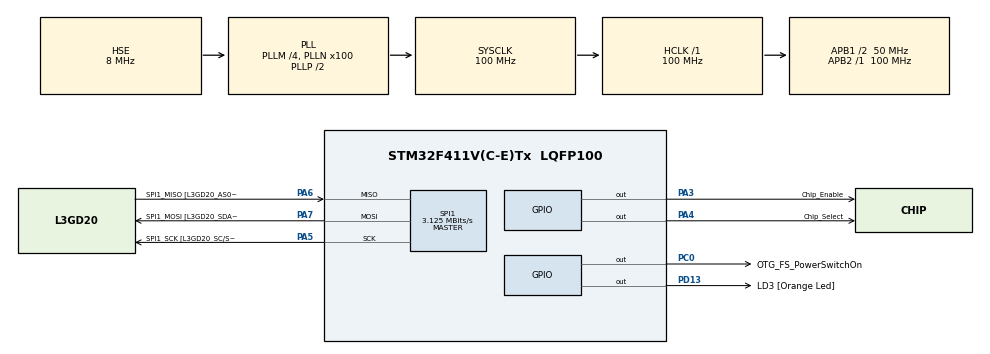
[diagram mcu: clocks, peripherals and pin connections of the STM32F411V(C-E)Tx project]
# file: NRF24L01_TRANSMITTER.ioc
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Mcu.Family=STM32F4
Mcu.Name=STM32F411V(C-E)Tx
Mcu.Package=LQFP100
NVIC.PriorityGroup=NVIC_PRIORITYGROUP_0
PA13.GPIO_Label=SWDIO
PA13.Mode=Serial_Wire
PA13.Signal=SYS_JTMS-SWDIO
PA14.GPIO_Label=SWCLK
PA14.Mode=Serial_Wire
PA14.Signal=SYS_JTCK-SWCLK
PA3.GPIO_Label=Chip_Enable
PA3.GPIO_PuPd=GPIO_PULLDOWN
PA3.GPIO_Speed=GPIO_SPEED_FREQ_MEDIUM
PA3.Signal=GPIO_Output
PA4.GPIO_Label=Chip_Select
PA4.GPIO_PuPd=GPIO_PULLUP
PA4.GPIO_Speed=GPIO_SPEED_FREQ_HIGH
PA4.PinState=GPIO_PIN_SET
PA4.Signal=GPIO_Output
PA5.GPIO_Label=SPI1_SCK [L3GD20_SC/SPC]
PA5.Mode=Full_Duplex_Master
PA5.Signal=SPI1_SCK
PA6.GPIO_Label=SPI1_MISO [L3GD20_AS0/SDO]
PA6.Mode=Full_Duplex_Master
PA6.Signal=SPI1_MISO
PA7.GPIO_Label=SPI1_MOSI [L3GD20_SDA/SDI/SDO]
PA7.Mode=Full_Duplex_Master
PA7.Signal=SPI1_MOSI
PB3.Signal=SYS_JTDO-SWO
PC0.GPIO_Label=OTG_FS_PowerSwitchOn
PC0.PinState=GPIO_PIN_SET
PC0.Signal=GPIO_Output
PD13.GPIO_Label=LD3 [Orange Led]
PD13.GPIO_PuPd=GPIO_NOPULL
PD13.GPIO_Speed=GPIO_SPEED_FREQ_LOW
PD13.Signal=GPIO_Output
PH0\ -\ OSC_IN.Mode=HSE-External-Oscillator
PH0\ -\ OSC_IN.Signal=RCC_OSC_IN
PH1\ -\ OSC_OUT.Mode=HSE-External-Oscillator
PH1\ -\ OSC_OUT.Signal=RCC_OSC_OUT
ProjectManager.HeapSize=0x200
ProjectManager.StackSize=0x400
ProjectManager.TargetToolchain=STM32CubeIDE
RCC.48MHZClocksFreq_Value=25000000
RCC.AHBFreq_Value=100000000
RCC.APB1CLKDivider=RCC_HCLK_DIV2
RCC.APB1Freq_Value=50000000
RCC.APB1TimFreq_Value=100000000
RCC.APB2Freq_Value=100000000
RCC.APB2TimFreq_Value=100000000
RCC.CortexFreq_Value=100000000
RCC.HCLKFreq_Value=100000000
RCC.HSE_VALUE=8000000
RCC.HSI_VALUE=16000000
RCC.PLLI2SM=5
RCC.PLLI2SN=200
RCC.PLLM=4
RCC.PLLN=100
RCC.PLLQ=8
RCC.PLLSourceVirtual=RCC_PLLSOURCE_HSE
RCC.SYSCLKFreq_VALUE=100000000
RCC.SYSCLKSource=RCC_SYSCLKSOURCE_PLLCLK
RCC.VCOOutputFreq_Value=200000000
SPI1.BaudRatePrescaler=SPI_BAUDRATEPRESCALER_32
SPI1.CalculateBaudRate=3.125 MBits/s
SPI1.Direction=SPI_DIRECTION_2LINES
SPI1.Mode=SPI_MODE_MASTER
SPI1.VirtualType=VM_MASTER
board=STM32F411E-DISCO

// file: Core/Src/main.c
/* USER CODE BEGIN Header */
/**
  ******************************************************************************
  * @file           : main.c
  * @brief          : Main program body
  ******************************************************************************
  * @attention
  *
  * Copyright (c) 2024 STMicroelectronics.
  * All rights reserved.
  *
  * This software is licensed under terms that can be found in the LICENSE file
  * in the root directory of this software component.
  * If no LICENSE file comes with this software, it is provided AS-IS.
  *
  ******************************************************************************
  */
/* USER CODE END Header */
#include "main.h"

/* USER CODE BEGIN Includes */
#include "NRF24L01.h"
#include "string.h"
#include "stdio.h"
/* USER CODE END Includes */

SPI_HandleTypeDef hspi1;

void SystemClock_Config(void);
static void MX_GPIO_Init(void);
static void MX_SPI1_Init(void);

/* USER CODE BEGIN 0 */
//uint8_t data[50];
uint8_t TxAddress[] = {0xAA, 0xBB, 0xCC, 0xDD, 0x11};  // 5-byte address for Pipe 1
uint8_t TxData[] = "Hello World\n";  // Transmitted data

/* USER CODE END 0 */

int main(void)
{

  /* MCU Configuration--------------------------------------------------------*/

  /* Reset of all peripherals, Initializes the Flash interface and the Systick. */
  HAL_Init();

  /* Configure the system clock */
  SystemClock_Config();

  /* Initialize all configured peripherals */
  MX_GPIO_Init();
  MX_SPI1_Init();
  /* USER CODE BEGIN 2 */
  NRF24_Init();

 // NRF24_RxMode(RxAddress, 10);

 NRF24_TxMode(TxAddress, 10);
  /* USER CODE END 2 */

  /* Infinite loop */
  while (1)
  {

    /* USER CODE BEGIN 3 */
	  if (NRF24_Transmit(TxData) == 1)
	   	  {
	   		  HAL_GPIO_TogglePin(GPIOD, GPIO_PIN_13);
	   	  }

	   	  HAL_Delay(1000);

  }
  /* USER CODE END 3 */
}

void SystemClock_Config(void)
{
  RCC_OscInitTypeDef RCC_OscInitStruct = {0};
  RCC_ClkInitTypeDef RCC_ClkInitStruct = {0};

  /** Configure the main internal regulator output voltage
  */
  __HAL_RCC_PWR_CLK_ENABLE();
  __HAL_PWR_VOLTAGESCALING_CONFIG(PWR_REGULATOR_VOLTAGE_SCALE1);

  /** Initializes the RCC Oscillators according to the specified parameters
  * in the RCC_OscInitTypeDef structure.
  */
  RCC_OscInitStruct.OscillatorType = RCC_OSCILLATORTYPE_HSE;
  RCC_OscInitStruct.HSEState = RCC_HSE_ON;
  RCC_OscInitStruct.PLL.PLLState = RCC_PLL_ON;
  RCC_OscInitStruct.PLL.PLLSource = RCC_PLLSOURCE_HSE;
  RCC_OscInitStruct.PLL.PLLM = 4;
  RCC_OscInitStruct.PLL.PLLN = 100;
  RCC_OscInitStruct.PLL.PLLP = RCC_PLLP_DIV2;
  RCC_OscInitStruct.PLL.PLLQ = 8;
  if (HAL_RCC_OscConfig(&RCC_OscInitStruct) != HAL_OK)
  {
    Error_Handler();
  }

  /** Initializes the CPU, AHB and APB buses clocks
  */
  RCC_ClkInitStruct.ClockType = RCC_CLOCKTYPE_HCLK|RCC_CLOCKTYPE_SYSCLK
                              |RCC_CLOCKTYPE_PCLK1|RCC_CLOCKTYPE_PCLK2;
  RCC_ClkInitStruct.SYSCLKSource = RCC_SYSCLKSOURCE_PLLCLK;
  RCC_ClkInitStruct.AHBCLKDivider = RCC_SYSCLK_DIV1;
  RCC_ClkInitStruct.APB1CLKDivider = RCC_HCLK_DIV2;
  RCC_ClkInitStruct.APB2CLKDivider = RCC_HCLK_DIV1;

  if (HAL_RCC_ClockConfig(&RCC_ClkInitStruct, FLASH_LATENCY_3) != HAL_OK)
  {
    Error_Handler();
  }
}

static void MX_SPI1_Init(void)
{

  /* SPI1 parameter configuration*/
  hspi1.Instance = SPI1;
  hspi1.Init.Mode = SPI_MODE_MASTER;
  hspi1.Init.Direction = SPI_DIRECTION_2LINES;
  hspi1.Init.DataSize = SPI_DATASIZE_8BIT;
  hspi1.Init.CLKPolarity = SPI_POLARITY_LOW;
  hspi1.Init.CLKPhase = SPI_PHASE_1EDGE;
  hspi1.Init.NSS = SPI_NSS_SOFT;
  hspi1.Init.BaudRatePrescaler = SPI_BAUDRATEPRESCALER_32;
  hspi1.Init.FirstBit = SPI_FIRSTBIT_MSB;
  hspi1.Init.TIMode = SPI_TIMODE_DISABLE;
  hspi1.Init.CRCCalculation = SPI_CRCCALCULATION_DISABLE;
  hspi1.Init.CRCPolynomial = 10;
  if (HAL_SPI_Init(&hspi1) != HAL_OK)
  {
    Error_Handler();
  }

}

static void MX_GPIO_Init(void)
{
  GPIO_InitTypeDef GPIO_InitStruct = {0};

  /* GPIO Ports Clock Enable */
  __HAL_RCC_GPIOH_CLK_ENABLE();
  __HAL_RCC_GPIOC_CLK_ENABLE();
  __HAL_RCC_GPIOA_CLK_ENABLE();
  __HAL_RCC_GPIOD_CLK_ENABLE();
  __HAL_RCC_GPIOB_CLK_ENABLE();

  /*Configure GPIO pin Output Level */
  HAL_GPIO_WritePin(OTG_FS_PowerSwitchOn_GPIO_Port, OTG_FS_PowerSwitchOn_Pin, GPIO_PIN_SET);

  /*Configure GPIO pin Output Level */
  HAL_GPIO_WritePin(Chip_Enable_GPIO_Port, Chip_Enable_Pin, GPIO_PIN_RESET);

  /*Configure GPIO pin Output Level */
  HAL_GPIO_WritePin(Chip_Select_GPIO_Port, Chip_Select_Pin, GPIO_PIN_SET);

  /*Configure GPIO pin Output Level */
  HAL_GPIO_WritePin(LD3_GPIO_Port, LD3_Pin, GPIO_PIN_RESET);

  /*Configure GPIO pin : OTG_FS_PowerSwitchOn_Pin */
  GPIO_InitStruct.Pin = OTG_FS_PowerSwitchOn_Pin;
  GPIO_InitStruct.Mode = GPIO_MODE_OUTPUT_PP;
  GPIO_InitStruct.Pull = GPIO_NOPULL;
  GPIO_InitStruct.Speed = GPIO_SPEED_FREQ_LOW;
  HAL_GPIO_Init(OTG_FS_PowerSwitchOn_GPIO_Port, &GPIO_InitStruct);

  /*Configure GPIO pin : Chip_Enable_Pin */
  GPIO_InitStruct.Pin = Chip_Enable_Pin;
  GPIO_InitStruct.Mode = GPIO_MODE_OUTPUT_PP;
  GPIO_InitStruct.Pull = GPIO_PULLDOWN;
  GPIO_InitStruct.Speed = GPIO_SPEED_FREQ_MEDIUM;
  HAL_GPIO_Init(Chip_Enable_GPIO_Port, &GPIO_InitStruct);

  /*Configure GPIO pin : Chip_Select_Pin */
  GPIO_InitStruct.Pin = Chip_Select_Pin;
  GPIO_InitStruct.Mode = GPIO_MODE_OUTPUT_PP;
  GPIO_InitStruct.Pull = GPIO_PULLUP;
  GPIO_InitStruct.Speed = GPIO_SPEED_FREQ_HIGH;
  HAL_GPIO_Init(Chip_Select_GPIO_Port, &GPIO_InitStruct);

  /*Configure GPIO pin : LD3_Pin */
  GPIO_InitStruct.Pin = LD3_Pin;
  GPIO_InitStruct.Mode = GPIO_MODE_OUTPUT_PP;
  GPIO_InitStruct.Pull = GPIO_NOPULL;
  GPIO_InitStruct.Speed = GPIO_SPEED_FREQ_LOW;
  HAL_GPIO_Init(LD3_GPIO_Port, &GPIO_InitStruct);

}

void Error_Handler(void)
{
  __disable_irq();
  while (1)
  {
  }
}
